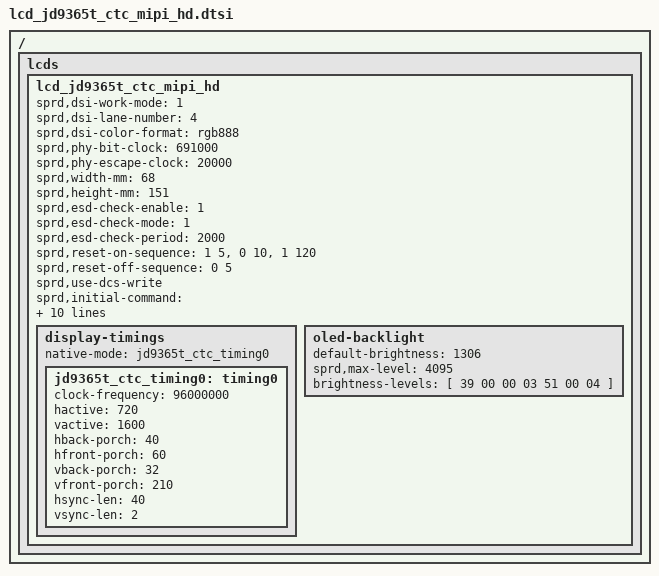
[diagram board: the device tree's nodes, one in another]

/*
 * R61350 Truly LCD config dtsi file for spreadtrum
 *
 * Copyright (C) 2018, Spreadtrum Communications Inc.
 *
 * SPDX-License-Identifier: (GPL-2.0+ OR MIT)
 */

/ {
	fragment {
		target-path = "/";
		__overlay__ {
			lcds {
				lcd_jd9365t_ctc_mipi_hd: lcd_jd9365t_ctc_mipi_hd {

					sprd,dsi-work-mode = <1>; /* video burst mode*/
					sprd,dsi-lane-number = <4>;
					sprd,dsi-color-format = "rgb888";

					sprd,phy-bit-clock = <691000>;	/* kbps */
					sprd,phy-escape-clock = <20000>;/* kHz */

					sprd,width-mm = <68>;
					sprd,height-mm = <151>;

					sprd,esd-check-enable = <1>;
					sprd,esd-check-mode = <1>;
					sprd,esd-check-period = <2000>;
					/* sprd,esd-check-register = <0x0A>; */
					/* sprd,esd-check-value = <0x9C>; */

					sprd,reset-on-sequence = <1 5>, <0 10>, <1 120>;
					sprd,reset-off-sequence = <0 5>;

 
					sprd,use-dcs-write;
					sprd,initial-command = [
					39 00 00 04 df 93 83 16
					39 00 00 02 de 00
					39 00 00 13 b3 10 80 85 00 65 1e 00 00 00 00 64 64 3c 3c 33 11 5a 5a
					39 00 00 06 b2 01 23 60 88 24
					39 00 00 04 b6 0c 99 ae
					39 00 00 04 b9 3c 33 35
					39 00 00 08 bb 0c 31 43 64 3c 20 20
					39 00 00 03 bd 00 b1
					39 00 00 06 c0 00 d5 10 d5 10
					39 00 00 2b cb 5e 55 4c 3e 32 2e 20 25 0f 28 27 26 40 2b 31 21 22 15 0b 04 02 5e 55 4c 3e 32 2e 20 25 0f 28 27 26 40 2b 31 21 22 15 0b 04 02
					39 00 00 03 cd 10 10
					39 00 00 05 bf 5a 3c 33 c3
					39 00 00 0e c3 13 00 06 16 99 00 9e 08 16 04 18 08 16
					39 00 00 0b c5 30 20 87 00 00 00 00 38 00 11
					39 00 00 05 c6 00 b6 d2 14
					39 00 00 13 ce 01 3c 00 00 00 3c 00 3c 3f 3f 00 3c 3c 3c 3c 00 3c 3c
					39 00 00 11 cf 00 00 00 00 00 00 c0 c0 c0 c0 c0 c0 c0 c0 c0 c0
					39 00 00 1e d0 00 1f 1f 1f 1f 1f 1f 15 15 16 1f 05 07 09 0b 1f 01 03 1f 1f 1f 1f 1f 00 00 00 00 00 00
					39 00 00 1e d1 00 1f 1f 1f 1f 1f 1f 15 15 16 1f 04 06 08 0a 1f 00 02 1f 1f 1f 1f 1f 00 00 00 00 00 00
					39 00 00 1e d2 00 1f 1f 1f 1f 15 1f 1f 15 16 1f 0a 08 06 04 1f 02 00 1f 1f 1f 1f 1f 00 00 00 03 00 00
					39 00 00 1e d3 00 1f 1f 1f 1f 15 1f 1f 15 16 1f 0b 09 07 05 1f 03 01 1f 1f 1f 1f 1f 00 00 00 03 00 00
					39 00 00 3f d4 30 00 00 07 00 09 00 00 00 00 00 06 06 00 10 26 54 00 04 03 03 00 01 00 04 01 01 11 60 03 00 05 01 01 00 00 06 04 07 06 55 06 53 00 00 00 00 00 00 00 00 00 00 00 00 00 00 00 00 81 03 d4
					39 00 00 1c d5 03 10 03 00 01 00 00 00 00 43 00 00 00 07 32 5a 00 48 77 00 02 1e 02 73 00 0e 08
					39 00 00 14 d7 00 7c 7c 7c 7c 7c 7c 7c 7c 7c 7c 7c 7c 7c 7c 7c 7c 7c 7c
					39 00 00 02 de 01
					39 00 00 02 b5 6f
					39 00 00 03 c5 22 12
					39 00 00 08 c6 3f 0c 00 00 01 80 60
					39 00 00 02 de 02
					39 00 00 06 b3 20 a0 ea 5f 4b
					39 00 00 09 b7 44 00 88 00 03 00 6e 10
					39 00 00 02 bd 14
					39 00 00 09 c1 00 40 20 00 14 14 14 14
					39 00 00 08 c2 42 70 01 01 e0 73 f8
					39 00 00 07 c3 20 fb 00 a0 20 62
					39 00 00 0b e5 00 e6 e5 02 27 42 27 42 09 00
					39 00 00 04 e6 10 20 a9
					39 00 00 04 ec 01 7f 22
					39 00 00 02 de 03
					39 00 00 02 d1 00
					39 00 00 02 de 00
					39 00 00 02 35 00
					39 00 00 03 51 0f ff
					39 00 00 02 53 2c
					39 00 00 02 de 00
					39 32 00 02 55 90
					05 96 00 02 11 00
					39 00 00 02 de 01
					39 00 00 02 b3 06
					39 00 00 21 b4 03 45 31 00 28 75 50 1e 1f 21 21 21 1e 1c 1a 1c 1e 21 22 22 22 22 22 22 22 22 21 21 21 21 1f 88
					39 32 00 02 de 00
					05 14 00 02 29 00
						];

					sprd,sleep-in-command = [
						15 40 00 01 28
						15 78 00 01 10
					  ];

					sprd,sleep-out-command = [
						15 78 00 01 11
						15 14 00 01 29
					  ];                 

					sprd,cabc-off-command = [
					  23 00 00 02 55 00
					  ];
					sprd,cabc-ui-command = [
					  23 00 00 02 55 01
					  ];
					sprd,cabc-still-image-command = [
					  23 00 00 02 55 02
					  ];
					sprd,cabc-video-command = [
					  23 00 00 02 55 03
					  ];
					display-timings {
						native-mode = <&jd9365t_ctc_timing0>;
						jd9365t_ctc_timing0: timing0 {
							clock-frequency = <96000000>;
							hactive = <720>;
							vactive = <1600>;
							hback-porch = <40>;
							hfront-porch = <60>;
							vback-porch = <32>;
							vfront-porch = <210>;
							hsync-len = <40>;
							vsync-len = <2>;
						};
					};

					
					oled-backlight {			
						default-brightness = <1306>;	
						sprd,max-level = <4095>;
						brightness-levels = [				
						39 00 00 03 51 00 04	
						];
					};
				};
			};
		};
	};
};
